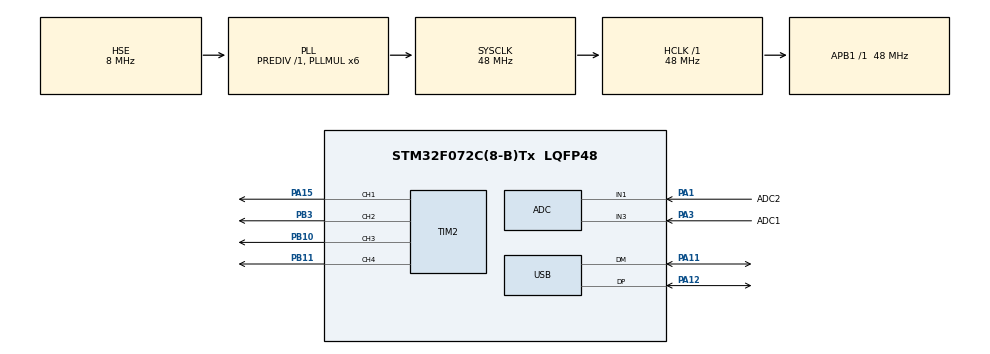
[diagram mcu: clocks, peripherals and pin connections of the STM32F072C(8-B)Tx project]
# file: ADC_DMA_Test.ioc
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ADC.ExternalTrigConv=ADC_EXTERNALTRIGCONV_T2_TRGO
ADC.ExternalTrigConvEdge=ADC_EXTERNALTRIGCONVEDGE_RISING
Dma.ADC.0.Direction=DMA_PERIPH_TO_MEMORY
Dma.ADC.0.Instance=DMA1_Channel1
Dma.ADC.0.MemDataAlignment=DMA_MDATAALIGN_HALFWORD
Dma.ADC.0.MemInc=DMA_MINC_ENABLE
Dma.ADC.0.Mode=DMA_NORMAL
Dma.ADC.0.PeriphDataAlignment=DMA_PDATAALIGN_HALFWORD
Dma.ADC.0.PeriphInc=DMA_PINC_DISABLE
Dma.ADC.0.Priority=DMA_PRIORITY_VERY_HIGH
Dma.Request0=ADC
Mcu.Family=STM32F0
Mcu.Name=STM32F072C(8-B)Tx
Mcu.Package=LQFP48
NVIC.DMA1_Channel1_IRQn=true\:0\:0\:false\:false\:true\:false\:true\:true
NVIC.USB_IRQn=true\:0\:0\:false\:false\:true\:false\:true\:true
PA1.GPIO_Label=ADC2
PA1.Mode=IN1
PA1.Signal=ADC_IN1
PA11.Mode=Device
PA11.Signal=USB_DM
PA12.Mode=Device
PA12.Signal=USB_DP
PA15.Signal=S_TIM2_CH1_ETR
PA3.GPIO_Label=ADC1
PA3.Mode=IN3
PA3.Signal=ADC_IN3
PB10.Signal=S_TIM2_CH3
PB11.Signal=S_TIM2_CH4
PB3.Signal=S_TIM2_CH2
PF0-OSC_IN.Mode=HSE-External-Oscillator
PF0-OSC_IN.Signal=RCC_OSC_IN
PF1-OSC_OUT.Mode=HSE-External-Oscillator
PF1-OSC_OUT.Signal=RCC_OSC_OUT
ProjectManager.HeapSize=0x200
ProjectManager.StackSize=0x400
ProjectManager.TargetToolchain=MDK-ARM V5.32
RCC.AHBFreq_Value=48000000
RCC.APB1Freq_Value=48000000
RCC.APB1TimFreq_Value=48000000
RCC.HCLKFreq_Value=48000000
RCC.PLLMUL=RCC_PLL_MUL6
RCC.PLLSourceVirtual=RCC_PLLSOURCE_HSE
RCC.SYSCLKFreq_VALUE=48000000
RCC.SYSCLKSource=RCC_SYSCLKSOURCE_PLLCLK
SH.S_TIM2_CH1_ETR.0=TIM2_CH1,PWM Generation1 CH1
SH.S_TIM2_CH2.0=TIM2_CH2,PWM Generation2 CH2
SH.S_TIM2_CH3.0=TIM2_CH3,PWM Generation3 CH3
SH.S_TIM2_CH4.0=TIM2_CH4,PWM Generation4 CH4
TIM2.Channel-PWM\ Generation1\ CH1=TIM_CHANNEL_1
TIM2.Channel-PWM\ Generation2\ CH2=TIM_CHANNEL_2
TIM2.Channel-PWM\ Generation3\ CH3=TIM_CHANNEL_3
TIM2.Channel-PWM\ Generation4\ CH4=TIM_CHANNEL_4
TIM2.OCMode_PWM-PWM\ Generation1\ CH1=TIM_OCMODE_PWM2
TIM2.OCMode_PWM-PWM\ Generation2\ CH2=TIM_OCMODE_PWM2
TIM2.OCMode_PWM-PWM\ Generation3\ CH3=TIM_OCMODE_PWM2
TIM2.OCMode_PWM-PWM\ Generation4\ CH4=TIM_OCMODE_PWM2
TIM2.TIM_MasterOutputTrigger=TIM_TRGO_UPDATE
TIM2.TIM_MasterSlaveMode=TIM_MASTERSLAVEMODE_DISABLE
USB_DEVICE.CLASS_NAME_FS=CDC
USB_DEVICE.VirtualMode=Cdc
USB_DEVICE.VirtualModeFS=Cdc_FS
VP_TIM2_VS_ClockSourceINT.Mode=Internal
VP_USB_DEVICE_VS_USB_DEVICE_CDC_FS.Mode=CDC_FS
board=custom

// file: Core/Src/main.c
/* USER CODE BEGIN Header */
/**
  ******************************************************************************
  * @file           : main.c
  * @brief          : Main program body
  ******************************************************************************
  * @attention
  *
  * Copyright (c) 2025 STMicroelectronics.
  * All rights reserved.
  *
  * This software is licensed under terms that can be found in the LICENSE file
  * in the root directory of this software component.
  * If no LICENSE file comes with this software, it is provided AS-IS.
  *
  ******************************************************************************
  */
/* USER CODE END Header */
#include "main.h"
#include "adc.h"
#include "dma.h"
#include "tim.h"
#include "usb_device.h"
#include "gpio.h"

/* USER CODE BEGIN Includes */
#include "usb_printf.h"
/* USER CODE END Includes */

void SystemClock_Config(void);

int main(void)
{

  /* MCU Configuration--------------------------------------------------------*/

  /* Reset of all peripherals, Initializes the Flash interface and the Systick. */
  HAL_Init();

  /* Configure the system clock */
  SystemClock_Config();

  /* Initialize all configured peripherals */
  MX_GPIO_Init();
  MX_DMA_Init();
  MX_ADC_Init();
  MX_TIM2_Init();
  MX_USB_DEVICE_Init();
  /* USER CODE BEGIN 2 */
  HAL_Delay(3000);
  uint32_t dma_buf[2]={0};
  HAL_TIM_Base_Start(&htim2);
	HAL_ADC_Start_DMA(&hadc, (uint32_t *)&dma_buf[0], 2);

  /* USER CODE END 2 */

  /* Infinite loop */
  /* USER CODE BEGIN WHILE */
  while (1)
  {
		usb_printf("\r\ndma_buf[0]=%d\r\n",dma_buf[0]&0xffff);
		usb_printf("dma_buf[1]=%d\r\n",dma_buf[1]&0xffff);
		HAL_Delay(200);
    /* USER CODE END WHILE */

  }
}

void SystemClock_Config(void)
{
  RCC_OscInitTypeDef RCC_OscInitStruct = {0};
  RCC_ClkInitTypeDef RCC_ClkInitStruct = {0};
  RCC_PeriphCLKInitTypeDef PeriphClkInit = {0};

  /** Initializes the RCC Oscillators according to the specified parameters
  * in the RCC_OscInitTypeDef structure.
  */
  RCC_OscInitStruct.OscillatorType = RCC_OSCILLATORTYPE_HSI14|RCC_OSCILLATORTYPE_HSI48
                              |RCC_OSCILLATORTYPE_HSE;
  RCC_OscInitStruct.HSEState = RCC_HSE_ON;
  RCC_OscInitStruct.HSI48State = RCC_HSI48_ON;
  RCC_OscInitStruct.HSI14State = RCC_HSI14_ON;
  RCC_OscInitStruct.HSI14CalibrationValue = 16;
  RCC_OscInitStruct.PLL.PLLState = RCC_PLL_ON;
  RCC_OscInitStruct.PLL.PLLSource = RCC_PLLSOURCE_HSE;
  RCC_OscInitStruct.PLL.PLLMUL = RCC_PLL_MUL6;
  RCC_OscInitStruct.PLL.PREDIV = RCC_PREDIV_DIV1;
  if (HAL_RCC_OscConfig(&RCC_OscInitStruct) != HAL_OK)
  {
    Error_Handler();
  }

  /** Initializes the CPU, AHB and APB buses clocks
  */
  RCC_ClkInitStruct.ClockType = RCC_CLOCKTYPE_HCLK|RCC_CLOCKTYPE_SYSCLK
                              |RCC_CLOCKTYPE_PCLK1;
  RCC_ClkInitStruct.SYSCLKSource = RCC_SYSCLKSOURCE_PLLCLK;
  RCC_ClkInitStruct.AHBCLKDivider = RCC_SYSCLK_DIV1;
  RCC_ClkInitStruct.APB1CLKDivider = RCC_HCLK_DIV1;

  if (HAL_RCC_ClockConfig(&RCC_ClkInitStruct, FLASH_LATENCY_1) != HAL_OK)
  {
    Error_Handler();
  }
  PeriphClkInit.PeriphClockSelection = RCC_PERIPHCLK_USB;
  PeriphClkInit.UsbClockSelection = RCC_USBCLKSOURCE_HSI48;

  if (HAL_RCCEx_PeriphCLKConfig(&PeriphClkInit) != HAL_OK)
  {
    Error_Handler();
  }
}

void Error_Handler(void)
{
  __disable_irq();
  while (1)
  {
  }
}
